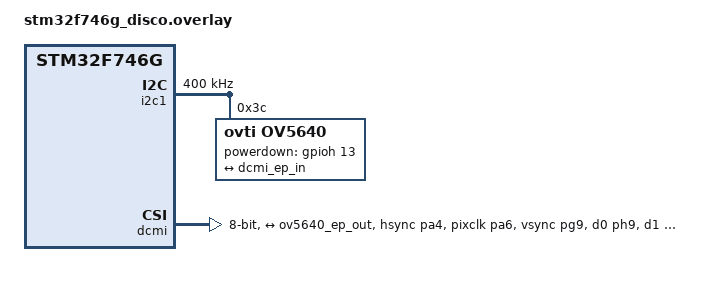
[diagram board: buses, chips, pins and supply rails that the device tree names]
/*
 * Copyright (c) 2024 Charles Dias <charlesdias.cd@outlook.com>
 *
 * SPDX-License-Identifier: Apache-2.0
 *
 */

&i2c1 {
	status = "okay";
	clock-frequency = <I2C_BITRATE_FAST>;

	ov5640: ov5640@3c {
		compatible = "ovti,ov5640";
		reg = <0x3c>;
		status = "okay";
		// reset-gpios = <&gpioa 0 GPIO_ACTIVE_LOW>;
		powerdown-gpios = <&gpioh 13 GPIO_ACTIVE_HIGH>;

		bus-type = <1>; /* Parallel */
		bus-width = <8>;

		port {
			ov5640_ep_out: endpoint {
				remote-endpoint = <&dcmi_ep_in>;
			};
		};
	};
};
&dcmi {
	status = "okay";
	sensor = <&ov5640>;
	pinctrl-0 = <&dcmi_hsync_pa4 &dcmi_pixclk_pa6 &dcmi_vsync_pg9
		&dcmi_d0_ph9 &dcmi_d1_ph10 &dcmi_d2_ph11 &dcmi_d3_ph12
		&dcmi_d4_ph14 &dcmi_d5_pd3 &dcmi_d6_pe5 &dcmi_d7_pe6>;
	pinctrl-names = "default";
	bus-width = <8>;
	hsync-active = <0>;
	vsync-active = <0>;
	pixelclk-active = <1>;
	capture-rate = <1>;
	dmas = <&dma1 0 1 (STM32_DMA_PERIPH_TO_MEMORY | STM32_DMA_PERIPH_NO_INC |
		STM32_DMA_MEM_INC | STM32_DMA_PERIPH_8BITS | STM32_DMA_MEM_32BITS |
		STM32_DMA_PRIORITY_HIGH) STM32_DMA_FIFO_FULL>;

	port {
		dcmi_ep_in: endpoint {
			remote-endpoint = <&ov5640_ep_out>;
		};
	};
};

&dma1 {
	status = "okay";
};
